AUTOSAR XML (schema 00048)
standard types defined: uint8, uint8_DataConstr
package /ComponentTypes
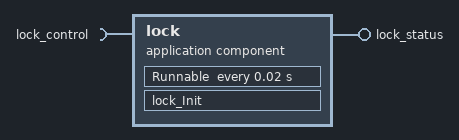
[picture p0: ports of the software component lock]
  application sw component type lock
    require port lock_control: nonqueued-receiver-com-spec{data-element=lock_cmd, init-value=ComSpecb5aae9b5_459533bbeac83fec:0}, required-interface=lock_control
    provide port lock_status: nonqueued-sender-com-spec{data-element=lock_status, init-value=ComSpec4e671118_4431b2787bc93c50:0}, provided-interface=lock_status
    behavior lock_InternalBehavior: handle-termination-and-restart=NO-SUPPORT
      timing event TMT_Runnable: start-on-event=Runnable, period=0.02
      runnable Runnable
        data-receive-point-by-arguments:
          access IN_lock_control_lock_cmd: accessed-variable=lock_control.lock_cmd
        data-send-points:
          access OUT_lock_status_lock_status: accessed-variable=lock_status.lock_status
      runnable lock_Init
package /PortInterfaces
  sender receiver interface lock_control: invalidation-policy{data-element=lock_cmd, handle-invalid=DONT-INVALIDATE}
    data lock_cmd: category=VALUE, type=uint8
  sender receiver interface lock_status: invalidation-policy{data-element=lock_status, handle-invalid=DONT-INVALIDATE}
    data lock_status: category=VALUE, type=uint8
